# CY8C5868LTI_LP039 register map
File version: 0.1
CY8C58LP
Registers are 8-bit, read-write, no defined reset value unless marked. A register's access mark holds for its fields unless they carry their own. Offsets are from the block's base; lines under a group give offsets from that group; [hi:lo] are bit positions; {n}, {i} and the like mark numbered series; 'fields as' and 'values as' point back to an identical list; <NAME> marks a mode.

## Memory map
0x00000000 USBUART_1 — USBFS
0x00000000 Timer_Speedometer

## USBUART_1 — USBFS
Base 0x00000000
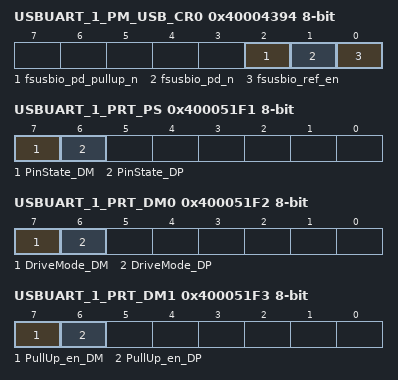
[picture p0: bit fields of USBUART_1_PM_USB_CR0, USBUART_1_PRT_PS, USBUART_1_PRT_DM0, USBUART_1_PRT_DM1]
0x40004394 USBUART_1_PM_USB_CR0 — USB Power Mode Control Register 0
  [2] fsusbio_pd_pullup_n, [1] fsusbio_pd_n, [0] fsusbio_ref_en
0x400043A5 USBUART_1_PM_ACT_CFG — Active Power Mode Configuration Register
0x400043B5 USBUART_1_PM_STBY_CFG — Standby Power Mode Configuration Register
0x400051F1 USBUART_1_PRT_PS — Port Pin State Register
  [7] PinState_DM ro, [6] PinState_DP ro
0x400051F2 USBUART_1_PRT_DM0 — Port Drive Mode Register
  [7] DriveMode_DM, [6] DriveMode_DP
0x400051F3 USBUART_1_PRT_DM1 — Port Drive Mode Register
  [7] PullUp_en_DM, [6] PullUp_en_DP
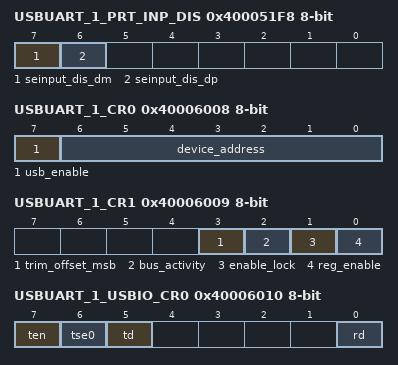
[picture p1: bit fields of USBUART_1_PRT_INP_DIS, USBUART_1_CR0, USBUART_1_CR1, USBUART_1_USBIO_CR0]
0x400051F8 USBUART_1_PRT_INP_DIS — Input buffer disable override
  [7] seinput_dis_dm, [6] seinput_dis_dp
0x40006000 USBUART_1_EP0_DR0 — bmRequestType
0x40006001 USBUART_1_EP0_DR1 — bRequest
0x40006002 USBUART_1_EP0_DR2 — wValueLo
0x40006003 USBUART_1_EP0_DR3 — wValueHi
0x40006004 USBUART_1_EP0_DR4 — wIndexLo
0x40006005 USBUART_1_EP0_DR5 — wIndexHi
0x40006006 USBUART_1_EP0_DR6 — lengthLo
0x40006007 USBUART_1_EP0_DR7 — lengthHi
0x40006008 USBUART_1_CR0 — USB Control Register 0
  [7] usb_enable, [6:0] device_address ro
0x40006009 USBUART_1_CR1 — USB Control Register 1
  [3] trim_offset_msb, [2] bus_activity, [1] enable_lock, [0] reg_enable
{0x40005FFE+0x10*i} USBUART_1_SIE_EP{i}_CR0 (i=1..8) — The Endpoint{i} Control Register
0x40006010 USBUART_1_USBIO_CR0 — USBIO Control Register 0
  [7] ten, [6] tse0, [5] td, [0] rd ro
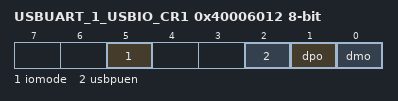
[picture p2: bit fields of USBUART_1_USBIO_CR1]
0x40006012 USBUART_1_USBIO_CR1 — USBIO Control Register 1
  [5] iomode, [2] usbpuen, [1] dpo ro, [0] dmo ro
0x4000608C USBUART_1_BUF_SIZE — Dedicated Endpoint Buffer Size Register
0x4000608E USBUART_1_EP_ACTIVE — Endpoint Active Indication Register
0x4000608F USBUART_1_EP_TYPE — Endpoint Type (IN/OUT) Indication
0x4000609D USBUART_1_USB_CLK_EN — USB Block Clock Enable Register

## Timer_Speedometer
Base 0x00000000
0x40006402 Timer_Speedometer_COUNTER 16-bit — UDB.A0 - Current Down Counter Value
0x40006422 Timer_Speedometer_PERIOD 16-bit — UDB.D0 - Assigned Period
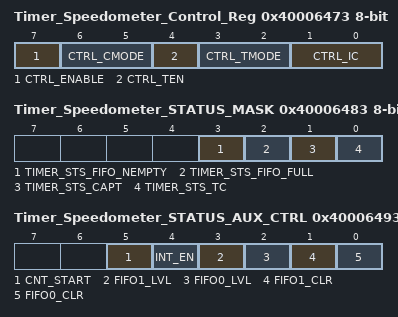
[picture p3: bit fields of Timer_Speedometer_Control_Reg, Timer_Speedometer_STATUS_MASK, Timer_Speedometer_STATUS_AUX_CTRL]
0x40006473 Timer_Speedometer_Control_Reg — UDB Control Register - Assigned Control Register Value
  [7] CTRL_ENABLE — Enable the Timer
  [6:5] CTRL_CMODE — Capture Mode
  [4] CTRL_TEN — Trigger Enable Bit
  [3:2] CTRL_TMODE — Trigger Mode
  [1:0] CTRL_IC — Interrupt Count
0x40006483 Timer_Speedometer_STATUS_MASK — UDB Status bits Interrupt Mask Enable Register
  [3] TIMER_STS_FIFO_NEMPTY ro — FIFO Empty status
  [2] TIMER_STS_FIFO_FULL ro — FIFO Full Status
  [1] TIMER_STS_CAPT ro — Enables the Interrupt on Capture
  [0] TIMER_STS_TC ro — Enables the Interrupt on TC
0x40006493 Timer_Speedometer_STATUS_AUX_CTRL — UDB Auxilliary Control Register
  [5] CNT_START — FIFO0 clear
    0=E_CNT_START0 (Disable counter); 1=E_CNT_START1 (Enable counter)
  [4] INT_EN
    0=E_INT_EN0 (Interrupt disabled); 1=E_INT_EN1 (Interrupt enabled)
  [3] FIFO1_LVL — FIFO level
    0=E_FIFO_LVL_0 (FIFO LVL: input mode: FIFO not full; output mode: FIFO not empty); 1=E_FIFO_LVL_1 (FIFO LVL: input mode: FIFO at least 1/2 empty; output mode: FIFO at least 1/2 full)
  [2] FIFO0_LVL — FIFO level
    values as FIFO1_LVL
  [1] FIFO1_CLR — FIFO1 clear
    0=E_FIFO_CLR_0 (Normal FIFO operation); 1=E_FIFO_CLR_1 (Clear FIFO state)
  [0] FIFO0_CLR — FIFO0 clear
    values as FIFO1_CLR
